# netx90_app register map
File version: 1.0
CPU: CM4 r0p1, little endian, MPU, FPU, 4 interrupt priority bits, 78 interrupts
Registers are 32-bit, read-write, reset 0x0 unless marked. A register's access mark holds for its fields unless they carry their own. Offsets are from the block's base; [hi:lo] are bit positions; {n}, {i} and the like mark numbered series.

## mled_ctrl_app
Base 0xFF801300
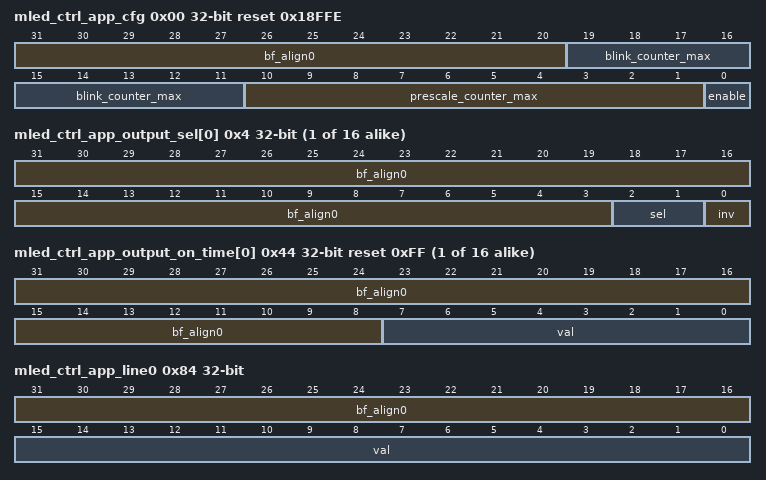
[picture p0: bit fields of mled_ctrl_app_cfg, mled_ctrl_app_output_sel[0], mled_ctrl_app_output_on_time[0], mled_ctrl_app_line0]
0x00 mled_ctrl_app_cfg reset 0x18FFE (reset mask 0xFFFFF) — Global configuration register. This register controls global configuration options for all Multi-LED outputs. Description of Multi-LED control module operation: a) Time-multiplexed PWM mode: Each output drives two LEDs: Low-side and high-side LED. Three states of the output pin are possible: High (i.e. the low-side LED is on), low (i.e. the high-side LED is on), or high-z (i.e. both LEDs are off). The PWM period, determined by bit field prescale_counter_max, is the same for all outputs. The prescale counter will be increased by the netX system clock (i.e. 100 MHz). A second counter (the PWM counter) will be increased when the prescale counter reaches its configured max. value. The PWM counter is a fixed-width counter and always counts from 0 to 511. If the PWM counter is in the range of 0 - 255, the high-side LED will be driven depending on the configured switch-on time (registers on_time[x], with x being an even number). The output pin will be driven low when the high-side phase starts. If the PWM counter reaches on_time[x] - 1, the output pin will switch to high-z state. If the PWM counter is in the range of 256 - 511, the low-side LED will be driven depending on the configured switch-on time (registers on_time[y], with y being an odd number). The output pin will be driven high when the low-side phase starts. If the PWM counter reaches 256 + on_time[y] - 1, the output pin will switch to high-z state. The state of an LED depends on the input value selected by the input multiplexer. For a list of selectable signals, see register mled_ctrl_output_sel[0]. When the selected input signal is off, the output signal will be high-z during the entire corresponding PWM phase. b) Pass-through mode: This mode disables the time-multiplexed PWM entirely and a configured signal will be output directly or inverted (delayed by one netX system cycle). This mode will be used when all bits of bit field sel of the output phase 0 configuration register (high-side LED) are set to '1'. The input signal (and inversion) is selected by the corresponding phase 1 configuration register (low-side LED). The output can be configured to high-z state if the corresponding phase 1 on_time register is set to '0', therefore it must be set != '0' for regular pass-through operation (i.e. the output will be driven high or low depending on the input signal). c) Multi-LED internal blink generator: The blink signal synchronizes the blinking of several LEDs. Bit field blink_counter_max determines the blink frequency which is the same for all outputs configured to blink mode.
  [31:20] bf_align0 — bitField alignment value for aeabi compatibility
  [19:11] blink_counter_max — Maximum value the blink counter will count to. The blink counter determines the blink frequency: f_blink = 50 Hz / (blink_counter_max + 1) blink_counter_max = (50 Hz / f_blink) - 1. The range of the blink frequency is therefore within ~0.1 Hz and 50 Hz.
  [10:1] prescale_counter_max — Maximum value the prescale counter will count to. The prescale counter determines the PWM frequency of all outputs: f_pwm = f_clk / (512 * (prescale_counter_max + 1)) prescale_counter_max = (f_clk / (512 * f_pwm)) - 1 with f_clk = 100 MHz (netX system frequency). The range of the PWM frequency is therefore within ~191 Hz and ~195 kHz.
  [0] enable — Writing a '1' to this bit will enable the MLED_CTRL_APP module. When disabled, all counters will be stopped to save power and outputs will be switched to high-z state.
{0x4+4i} mled_ctrl_app_output_sel[{i}] (i=0..15) (reset mask 0x7) — Output 0 phase 0 (high-side LED) configuration.
  [31:3] bf_align0 — bitField alignment value for aeabi compatibility
  [2:1] sel — Selection of the signal connected to this output. { | Value Input 0 always off 1 line register 2 MLED_CTRL blink 3 pass-through (for phase 0 registers) / reserved (for phase 1 registers) }
  [0] inv — Invert input signal.
{0x44+4i} mled_ctrl_app_output_on_time[{i}] (i=0..15) reset 0xFF (reset mask 0xFF) — Output 0 phase 0 (high-side LED) switch-on time.
  [31:8] bf_align0 — bitField alignment value for aeabi compatibility
  [7:0] val — Switch-on time of this LED. This value determines the period during which the output is active. The value helps achieve a consistent brightness of different LED types. Dimming individual LEDs is also possible. Possible values are 0 (off) to 255 (on for the full phase minus one PWM tick).
0x84 mled_ctrl_app_line0 (reset mask 0xFFFF) — Line register. The line register allows changing all LEDs (configured to line mode) at once to a new value. Note: The change will take effect at the start of the next PWM period (when the output operates in time-multiplexed PWM mode). In pass-through mode, the change will take effect immediately.
  [31:16] bf_align0 — bitField alignment value for aeabi compatibility
  [15:0] val — MLED output values 15..0 when line mode is selected in the corresponding 'sel' register.
